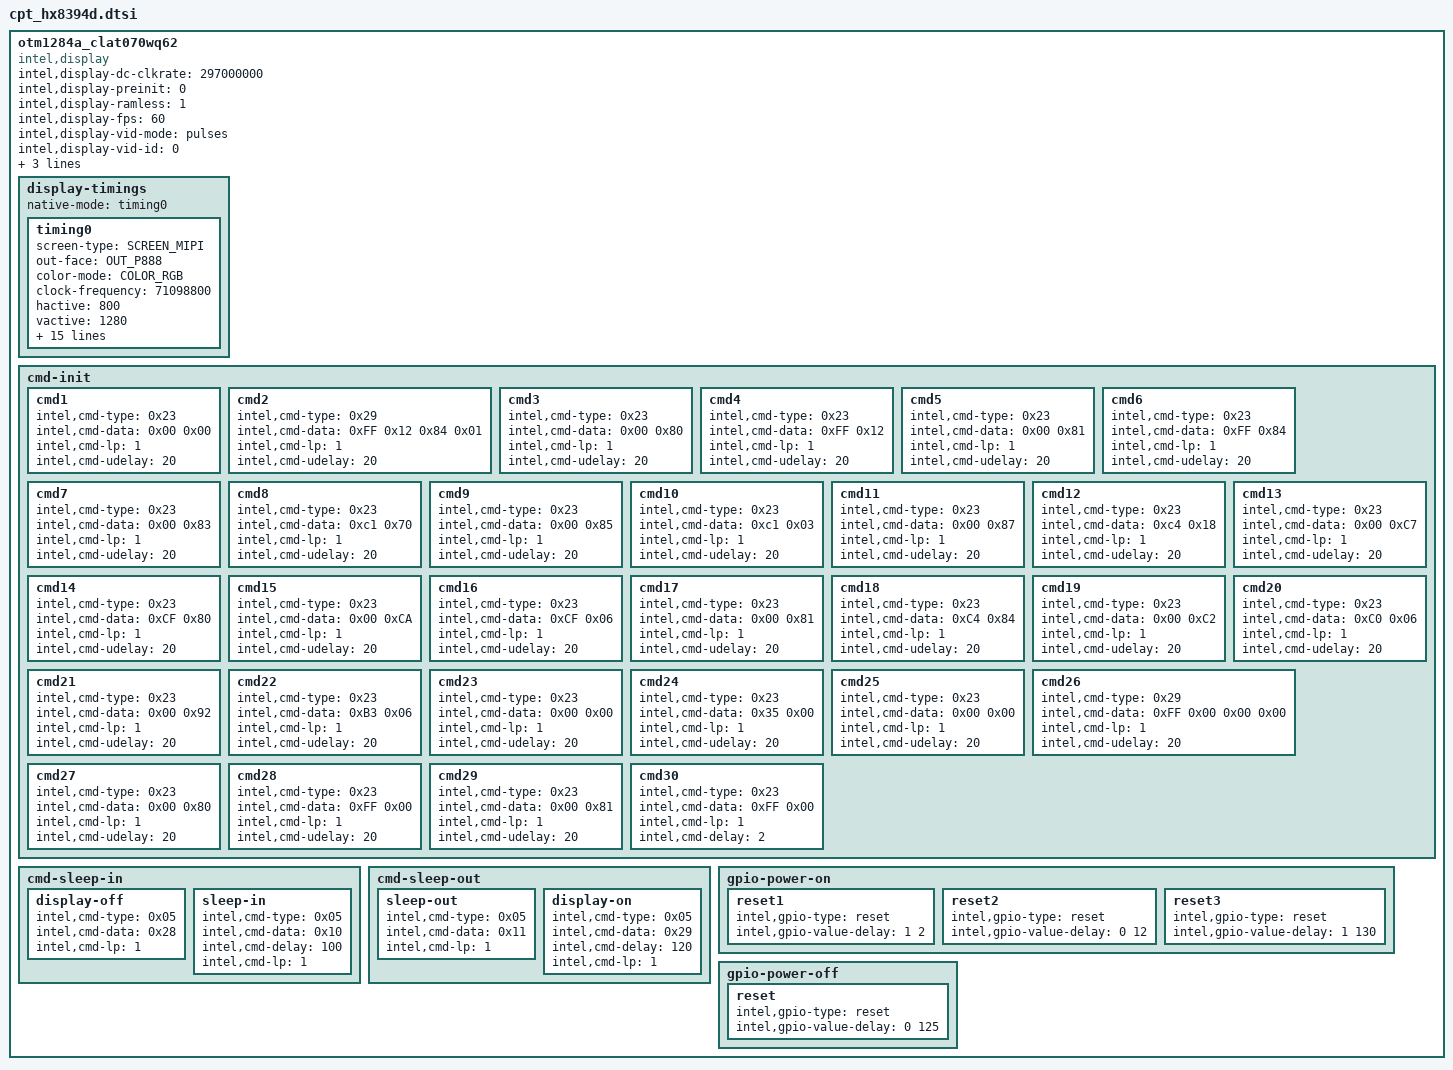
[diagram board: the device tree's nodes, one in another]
/*
 * definition at "include/dt-bindings/sofiafb/sofia_fb.h"
 */
otm1284a_clat070wq62 {
	compatible = "intel,display";
	intel,display-dc-clkrate = <297000000>;
	intel,display-preinit = <0>;
	intel,display-ramless = <1>;
	intel,display-fps = <60>;
	intel,display-vid-mode = "pulses";
	intel,display-vid-id = <0>;
	intel,display-if-nblanes = <4>;
	intel,display-eot = <0>;
	intel,display-gate = <0>;

        display-timings {
                native-mode = <&timing0>;
                timing0: timing0 {
                        screen-type = <SCREEN_MIPI>;
                        out-face    = <OUT_P888>;
                        color-mode = <COLOR_RGB>;
                        clock-frequency = <71098800>;
                        hactive = <800>;
                        vactive = <1280>;
                        hback-porch = <8>;
                        hfront-porch = <43>;
                        vback-porch = <20>;
                        vfront-porch = <20>;
                        hsync-len = <44>;
                        vsync-len = <4>;
                        hsync-active = <0>;
                        vsync-active = <0>;
                        de-active = <0>;
                        pixelclk-active = <0>;
                        swap-rb = <0>;
                        swap-rg = <0>;
                        swap-gb = <0>;
			width = <95>;
			height = <152>;
                };
        };

	cmd-init{
		cmd1 {
		intel,cmd-type = <0x23>;
		intel,cmd-data = <0x00 0x00>;
	        intel,cmd-lp = <1>;
		intel,cmd-udelay = <20>;
	};
                cmd2 {
                intel,cmd-type = <0x29>;
                intel,cmd-data = <0xFF 0x12 0x84 0x01>;
		intel,cmd-lp = <1>;
		intel,cmd-udelay = <20>;
        };
                cmd3 {
                intel,cmd-type = <0x23>;
                intel,cmd-data = <0x00 0x80>;
	        intel,cmd-lp = <1>;
		intel,cmd-udelay = <20>;
	};
	        cmd4 {
                intel,cmd-type = <0x23>;
                intel,cmd-data = <0xFF 0x12>;
	        intel,cmd-lp = <1>;
		intel,cmd-udelay = <20>;
	};
                cmd5 {
                intel,cmd-type = <0x23>;
                intel,cmd-data = <0x00 0x81>;
	        intel,cmd-lp = <1>;
		intel,cmd-udelay = <20>;
	};
                cmd6 {
                intel,cmd-type = <0x23>;
                intel,cmd-data = <0xFF 0x84>;
		intel,cmd-lp = <1>;
		intel,cmd-udelay = <20>;
	};
                cmd7 {                                            /* SSC +-3% */
                intel,cmd-type = <0x23>;
                intel,cmd-data = <0x00 0x83>;
		intel,cmd-lp = <1>;
		intel,cmd-udelay = <20>;
	};	
                cmd8 {
                intel,cmd-type = <0x23>;
                intel,cmd-data = <0xc1 0x70>;
		intel,cmd-lp = <1>;
		intel,cmd-udelay = <20>;
	};	
                cmd9 {                                            /* SSC En */
                intel,cmd-type = <0x23>;
                intel,cmd-data = <0x00 0x85>;
		intel,cmd-lp = <1>;
		intel,cmd-udelay = <20>;
	};
                cmd10 {
                intel,cmd-type = <0x23>;
                intel,cmd-data = <0xc1 0x03>;
		intel,cmd-lp = <1>;
		intel,cmd-udelay = <20>;
	};
                cmd11 {                                            /* OP Enable (PL and PCH) */
                intel,cmd-type = <0x23>;
                intel,cmd-data = <0x00 0x87>;
		intel,cmd-lp = <1>;
		intel,cmd-udelay = <20>;
	};
                cmd12 {
                intel,cmd-type = <0x23>;
                intel,cmd-data = <0xc4 0x18>;
		intel,cmd-lp = <1>;
		intel,cmd-udelay = <20>;
	};
                cmd13 {                                            /* Gate OP Enable */
                intel,cmd-type = <0x23>;
                intel,cmd-data = <0x00 0xC7>;
		intel,cmd-lp = <1>;
		intel,cmd-udelay = <20>;
	};
                cmd14 {
                intel,cmd-type = <0x23>;
                intel,cmd-data = <0xCF 0x80>;
		intel,cmd-lp = <1>;
		intel,cmd-udelay = <20>;
	};
                cmd15 {                                            /* Gate rising pre-charge */
                intel,cmd-type = <0x23>;
                intel,cmd-data = <0x00 0xCA>;
		intel,cmd-lp = <1>;
		intel,cmd-udelay = <20>;
	};
                cmd16 {
                intel,cmd-type = <0x23>;
                intel,cmd-data = <0xCF 0x06>;
		intel,cmd-lp = <1>;
		intel,cmd-udelay = <20>;
	};
                cmd17 {                                            /* Source Driver bias = 2.0 */
                intel,cmd-type = <0x23>;
                intel,cmd-data = <0x00 0x81>;
		intel,cmd-lp = <1>;
		intel,cmd-udelay = <20>;
	};
                cmd18 {
                intel,cmd-type = <0x23>;
                intel,cmd-data = <0xC4 0x84>;
		intel,cmd-lp = <1>;
		intel,cmd-udelay = <20>;
	};
                cmd19 {                                            /* Source Driver pre-charge */
                intel,cmd-type = <0x23>;
                intel,cmd-data = <0x00 0xC2>;
		intel,cmd-lp = <1>;
		intel,cmd-udelay = <20>;
	};
                cmd20 {
                intel,cmd-type = <0x23>;
                intel,cmd-data = <0xC0 0x06>;
		intel,cmd-lp = <1>;
		intel,cmd-udelay = <20>;
	};
                cmd21 {
                intel,cmd-type = <0x23>;
                intel,cmd-data = <0x00 0x92>;
		intel,cmd-lp = <1>;
		intel,cmd-udelay = <20>;
	};
                cmd22 {
                intel,cmd-type = <0x23>;
                intel,cmd-data = <0xB3 0x06>;
		intel,cmd-lp = <1>;
		intel,cmd-udelay = <20>;
	};
                cmd23 {
                intel,cmd-type = <0x23>;
                intel,cmd-data = <0x00 0x00>;
		intel,cmd-lp = <1>;
		intel,cmd-udelay = <20>;
	};
                cmd24 {
                intel,cmd-type = <0x23>;
                intel,cmd-data = <0x35 0x00>;
	        intel,cmd-lp = <1>;
		intel,cmd-udelay = <20>;
	};
                cmd25 {
                intel,cmd-type = <0x23>;
                intel,cmd-data = <0x00 0x00>;
		intel,cmd-lp = <1>;
		intel,cmd-udelay = <20>;
	};
                cmd26 {
                intel,cmd-type = <0x29>;
                intel,cmd-data = <0xFF 0x00 0x00 0x00>;
	        intel,cmd-lp = <1>;
		intel,cmd-udelay = <20>;
	};
                cmd27 {
                intel,cmd-type = <0x23>;
                intel,cmd-data = <0x00 0x80>;
		intel,cmd-lp = <1>;
		intel,cmd-udelay = <20>;
	};
                cmd28 {
                intel,cmd-type = <0x23>;
                intel,cmd-data = <0xFF 0x00>;
		intel,cmd-lp = <1>;
		intel,cmd-udelay = <20>;
	};
                cmd29 {
                intel,cmd-type = <0x23>;
                intel,cmd-data = <0x00 0x81>;
		intel,cmd-lp = <1>;
		intel,cmd-udelay = <20>;
	};
                cmd30 {
                intel,cmd-type = <0x23>;
                intel,cmd-data = <0xFF 0x00>;
		intel,cmd-lp = <1>;
		intel,cmd-delay = <2>;
	};
	};

	cmd-sleep-in {
		display-off{
			intel,cmd-type = <0x05>;
			intel,cmd-data = <0x28>;
			intel,cmd-lp = <1>;
		};
		sleep-in{
			intel,cmd-type = <0x05>;
			intel,cmd-data = <0x10>;
			intel,cmd-delay = <100>;
			intel,cmd-lp = <1>;
		};
	};

	cmd-sleep-out {
		sleep-out{
			intel,cmd-type = <0x05>;
			intel,cmd-data = <0x11>;
			intel,cmd-lp = <1>;
		};
		display-on{
			intel,cmd-type = <0x05>;
			intel,cmd-data = <0x29>;
			intel,cmd-delay = <120>;
			intel,cmd-lp = <1>;
		};
	};

       gpio-power-on {
               reset1 {
                       intel,gpio-type = "reset";
                       intel,gpio-value-delay = <1 2>;
               };
               reset2 {
                       intel,gpio-type = "reset";
                       intel,gpio-value-delay = <0 12>;
               };
               reset3 {
                       intel,gpio-type = "reset";
                       intel,gpio-value-delay = <1 130>;
               };
       };

       gpio-power-off {
               reset {
                       intel,gpio-type = "reset";
                       intel,gpio-value-delay = <0 125>;
               };
       };

};
